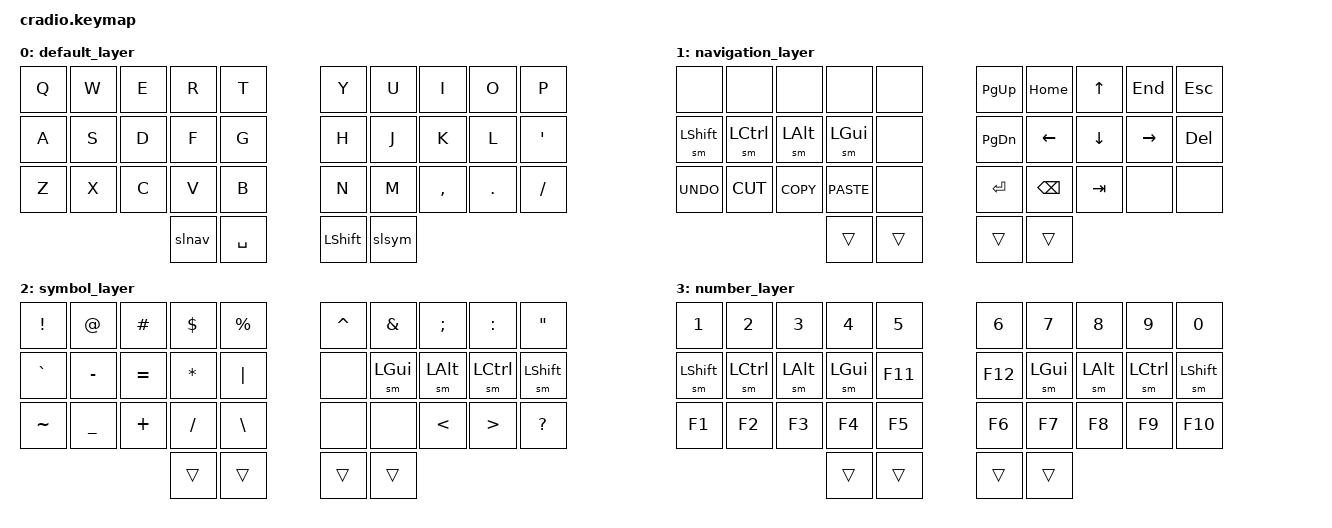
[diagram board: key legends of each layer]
/*
 * Copyright (c) 2023 The ZMK Contributors
 *
 * SPDX-License-Identifier: MIT
 */

#include <behaviors.dtsi>
#include <dt-bindings/zmk/keys.h>

/* Layers */
#define DEF_L 0
#define NAV_L 1
#define SYM_L 2
#define NUM_L 3

/* Shortcuts */
#define CUT LC(X)
#define COPY LC(C)
#define PASTE LC(V)
#define UNDO LC(Z)

/ {
    behaviors {
        lsk: lazy_sticky_key {
            compatible = "zmk,behavior-sticky-key";
            label = "LAZY_STICKY_KEY";
            #binding-cells = <1>;
            bindings = <&kp>;
            release-after-ms = <3000>;
            quick-release;
            ignore-modifiers;
            lazy;
        };

        sm: sticky_mod {
            compatible = "zmk,behavior-hold-tap";
            label = "STICKY_MOD";
            #binding-cells = <2>;
            bindings = <&kp>, <&lsk>;
            flavor = "balanced";
            hold-while-undecided;
        };
    };

    macros {
        slnav: sl_nav {
            label = "SL_NAV";
            compatible = "zmk,behavior-macro";
            #binding-cells = <0>;
            wait-ms = <0>;
            tap-ms = <0>;
            bindings
                = <&macro_tap &kp K_CANCEL>
                , <&macro_press &sl NAV_L>
                , <&macro_pause_for_release>
                , <&macro_release &sl NAV_L>
                ;
        };

        slsym: sl_sym {
            label = "SL_SYM";
            compatible = "zmk,behavior-macro";
            #binding-cells = <0>;
            wait-ms = <0>;
            tap-ms = <0>;
            bindings
                = <&macro_tap &kp K_CANCEL>
                , <&macro_press &sl SYM_L>
                , <&macro_pause_for_release>
                , <&macro_release &sl SYM_L>
                ;
        };
    };

    conditional_layers {
        compatible = "zmk,conditional-layers";
        tri_layer {
            if-layers = <NAV_L SYM_L>;
            then-layer = <NUM_L>;
        };
    };

    combos {
        compatible = "zmk,combos";

        /*                KEY POSITIONS

             0   1   2   3   4      5   6   7   8   9
            10  11  12  13  14     15  16  17  18  19
            20  21  22  23  24     25  26  27  28  29
                        30  31     32  33                */

        /* Brackets */
        lbkt { key-positions = <1 11>; bindings = <&kp LBKT>; layers = <DEF_L SYM_L NUM_L>; };
        rbkt { key-positions = <8 18>; bindings = <&kp RBKT>; layers = <DEF_L SYM_L NUM_L>; };
        lpar { key-positions = <2 12>; bindings = <&kp LPAR>; layers = <DEF_L SYM_L NUM_L>; };
        rpar { key-positions = <7 17>; bindings = <&kp RPAR>; layers = <DEF_L SYM_L NUM_L>; };
        lbrc { key-positions = <3 13>; bindings = <&kp LBRC>; layers = <DEF_L SYM_L NUM_L>; };
        rbrc { key-positions = <6 16>; bindings = <&kp RBRC>; layers = <DEF_L SYM_L NUM_L>; };
    }; 

    keymap {
        compatible = "zmk,keymap";
        default_layer {
            bindings = <
                &kp Q     &kp W     &kp E     &kp R     &kp T          &kp Y     &kp U     &kp I     &kp O     &kp P
                &kp A     &kp S     &kp D     &kp F     &kp G          &kp H     &kp J     &kp K     &kp L     &kp QUOT
                &kp Z     &kp X     &kp C     &kp V     &kp B          &kp N     &kp M     &kp COMMA &kp DOT   &kp FSLH
                                              &slnav    &kp SPACE      &kp LSHFT &slsym
            >;
        };
        navigation_layer {
            bindings = <
                &none     &none     &none     &none     &none          &kp PG_UP &kp HOME  &kp UP    &kp END   &kp ESC
                &sm LSHFT &sm LCTRL &sm LALT  &sm LGUI  &none          &kp PG_DN &kp LEFT  &kp DOWN  &kp RIGHT &kp DEL
                &kp UNDO  &kp CUT   &kp COPY  &kp PASTE &none          &kp ENTER &kp BSPC  &kp TAB   &none     &none
                                              &trans    &trans         &trans    &trans
            >;
        };
        symbol_layer {
            bindings = <
                &kp EXCL  &kp AT    &kp POUND &kp DLLR  &kp PRCNT      &kp CARET &kp AMPS  &kp SEMI  &kp COLON &kp DQT
                &kp GRAVE &kp MINUS &kp EQUAL &kp ASTRK &kp PIPE       &none     &sm LGUI  &sm LALT  &sm LCTRL &sm LSHFT
                &kp TILDE &kp UNDER &kp PLUS  &kp FSLH  &kp BSLH       &none     &none     &kp LT    &kp GT    &kp QMARK
                                              &trans    &trans         &trans    &trans
            >;
        };
        number_layer {
            bindings = <
                &kp 1     &kp 2     &kp 3     &kp 4     &kp 5          &kp 6     &kp 7     &kp 8     &kp 9     &kp 0
                &sm LSHFT &sm LCTRL &sm LALT  &sm LGUI  &kp F11        &kp F12   &sm LGUI  &sm LALT  &sm LCTRL &sm LSHFT
                &kp F1    &kp F2    &kp F3    &kp F4    &kp F5         &kp F6    &kp F7   &kp F8    &kp F9    &kp F10
                                              &trans    &trans         &trans    &trans
            >;
        };
    };
};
